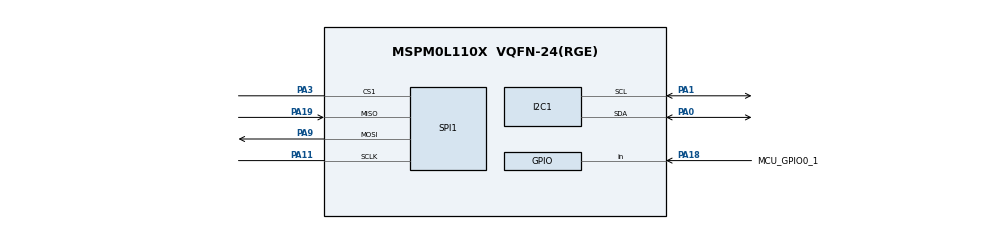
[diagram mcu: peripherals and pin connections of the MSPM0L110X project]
/**
 * @cliArgs --device "MSPM0L110X" --package "VQFN-24(RGE)" --part "Default" --product "mspm0_sdk@1.20.01.06"
 * @versions {"tool":"1.19.0+3426"}
 */

/**
 * Import the modules used in this configuration.
 */
const Board         = scripting.addModule("/ti/driverlib/Board");
const GPIO          = scripting.addModule("/ti/driverlib/GPIO", {}, false);
const GPIO1         = GPIO.addInstance();
const I2C           = scripting.addModule("/ti/driverlib/I2C", {}, false);
const I2C1          = I2C.addInstance();
const SPI           = scripting.addModule("/ti/driverlib/SPI", {}, false);
const SPI1          = SPI.addInstance();
const SYSCTL        = scripting.addModule("/ti/driverlib/SYSCTL");
const TIMER         = scripting.addModule("/ti/driverlib/TIMER", {}, false);
const TIMER1        = TIMER.addInstance();
const WWDT          = scripting.addModule("/ti/driverlib/WWDT", {}, false);
const WWDT1         = WWDT.addInstance();
const ProjectConfig = scripting.addModule("/ti/project_config/ProjectConfig");

/**
 * Write custom configuration values to the imported modules.
 */
Board.debugOn            = false;
Board.peripheral.$assign = "DEBUGSS";

GPIO1.port                          = "PORTA";
GPIO1.$name                         = "MCU_GPIO";
GPIO1.associatedPins[0].$name       = "MCU_GPIO0_1";
GPIO1.associatedPins[0].direction   = "INPUT";
GPIO1.associatedPins[0].assignedPin = "18";
GPIO1.associatedPins[0].pin.$assign = "PA18";

I2C1.basicEnableTarget                 = true;
I2C1.advEnableAfterInit                = false;
I2C1.advTargetTXEmptyEn                = true;
I2C1.basicTargetAddress                = 0x50;
I2C1.$name                             = "TAR_I2C";
I2C1.peripheral.$assign                = "I2C0";
I2C1.peripheral.sdaPin.$assign         = "PA0";
I2C1.peripheral.sclPin.$assign         = "PA1";
I2C1.sdaPinConfig.$name                = "ti_driverlib_gpio_GPIOPinGeneric0";
I2C1.sdaPinConfig.hideOutputInversion  = scripting.forceWrite(false);
I2C1.sdaPinConfig.onlyInternalResistor = scripting.forceWrite(false);
I2C1.sdaPinConfig.passedPeripheralType = scripting.forceWrite("Digital");
I2C1.sclPinConfig.$name                = "ti_driverlib_gpio_GPIOPinGeneric1";
I2C1.sclPinConfig.hideOutputInversion  = scripting.forceWrite(false);
I2C1.sclPinConfig.onlyInternalResistor = scripting.forceWrite(false);
I2C1.sclPinConfig.passedPeripheralType = scripting.forceWrite("Digital");

SPI1.$name                              = "PER_SPI";
SPI1.mode                               = "PERIPHERAL";
SPI1.peripheralChipSelect               = "1";
SPI1.peripheral.sclkPin.$assign         = "PA11";
SPI1.peripheral.mosiPin.$assign         = "PA9";
SPI1.peripheral.misoPin.$assign         = "PA19";
SPI1.peripheral.cs1Pin.$assign          = "PA3";
SPI1.sclkPinConfig.$name                = "ti_driverlib_gpio_GPIOPinGeneric2";
SPI1.sclkPinConfig.onlyInternalResistor = scripting.forceWrite(false);
SPI1.sclkPinConfig.passedPeripheralType = scripting.forceWrite("Digital");
SPI1.mosiPinConfig.$name                = "ti_driverlib_gpio_GPIOPinGeneric3";
SPI1.mosiPinConfig.hideOutputInversion  = scripting.forceWrite(false);
SPI1.mosiPinConfig.onlyInternalResistor = scripting.forceWrite(false);
SPI1.mosiPinConfig.passedPeripheralType = scripting.forceWrite("Digital");
SPI1.misoPinConfig.$name                = "ti_driverlib_gpio_GPIOPinGeneric4";
SPI1.misoPinConfig.onlyInternalResistor = scripting.forceWrite(false);
SPI1.misoPinConfig.passedPeripheralType = scripting.forceWrite("Digital");
SPI1.cs1PinConfig.$name                 = "ti_driverlib_gpio_GPIOPinGeneric5";

SYSCTL.EXCLKDivider       = "16";
SYSCTL.peripheral.$assign = "SYSCTL";

TIMER1.$name              = "WAKEUP_TIMER";
TIMER1.timerPeriod        = "500 ms";
TIMER1.timerMode          = "PERIODIC";
TIMER1.interrupts         = ["ZERO"];
TIMER1.timerClkSrc        = "LFCLK";
TIMER1.timerStartTimer    = true;
TIMER1.peripheral.$assign = "TIMG0";

WWDT1.$name              = "WWDT0";
WWDT1.periodCount        = "15";
WWDT1.clockDivider       = "5";
WWDT1.peripheral.$assign = "WWDT0";

ProjectConfig.genLinker  = false;
ProjectConfig.deviceSpin = "MSPM0L1105";

/**
 * Pinmux solution for unlocked pins/peripherals. This ensures that minor changes to the automatic solver in a future
 * version of the tool will not impact the pinmux you originally saw.  These lines can be completely deleted in order to
 * re-solve from scratch.
 */
SPI1.peripheral.$suggestSolution = "SPI0";
